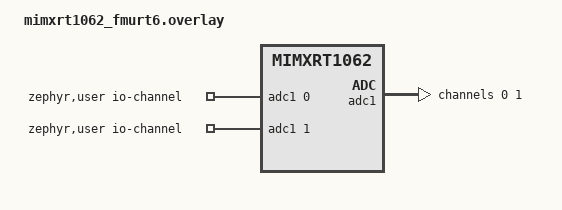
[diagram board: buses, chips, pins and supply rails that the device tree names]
/*
 * SPDX-License-Identifier: Apache-2.0
 *
 * Copyright 2023 NXP
 */

#include <zephyr/dt-bindings/adc/mcux-lpadc.h>

/ {
	zephyr,user {
		io-channels = <&adc1 0>, <&adc1 1>;
	};
};

&adc1 {
	#address-cells = <1>;
	#size-cells = <0>;

	channel@0 {
		reg = <0>;
		zephyr,gain = "ADC_GAIN_1";
		zephyr,reference = "ADC_REF_INTERNAL";
		zephyr,acquisition-time = <ADC_ACQ_TIME_DEFAULT>;
		zephyr,resolution = <12>;
	};

	channel@1 {
		reg = <1>;
		zephyr,gain = "ADC_GAIN_1";
		zephyr,reference = "ADC_REF_INTERNAL";
		zephyr,acquisition-time = <ADC_ACQ_TIME_DEFAULT>;
		zephyr,resolution = <12>;
	};
};
